AUTOSAR XML (schema 4-3-0)
standard types defined: Boolean, UInt8, SInt8, UInt16, SInt16, UInt32, SInt32, boolean, uint8, sint8, uint16, sint16, uint32, sint32
package /Components
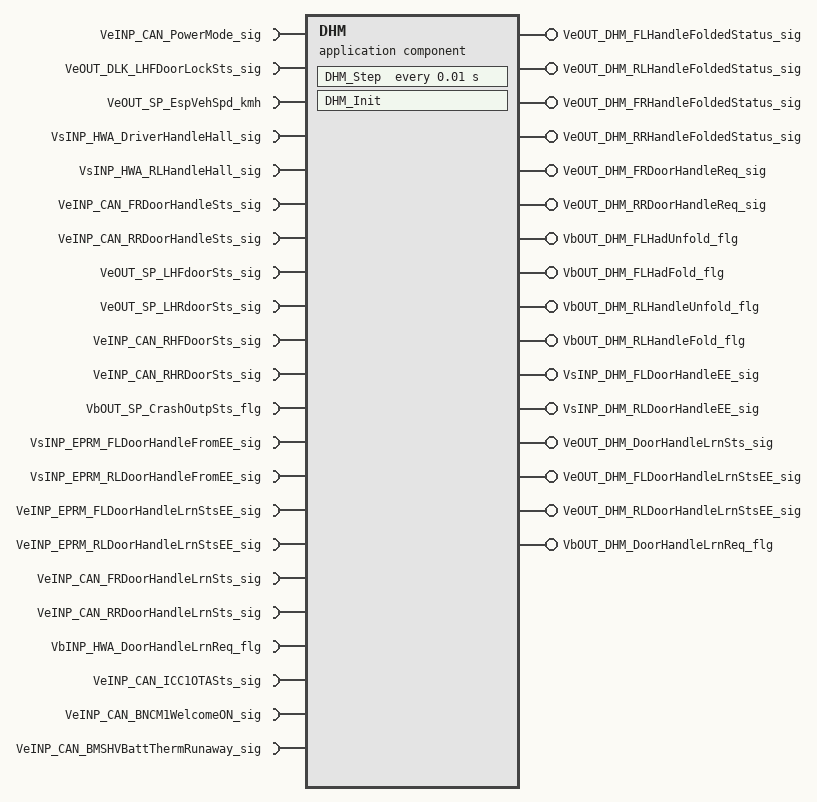
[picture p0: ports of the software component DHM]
  application sw component type DHM
    22 x require port:
      VeINP_CAN_PowerMode_sig: nonqueued-receiver-com-spec{data-element=VeINP_CAN_PowerMode_sig, init-value=0}, required-interface=VeINP_CAN_PowerMode_sig
      VeOUT_DLK_LHFDoorLockSts_sig: nonqueued-receiver-com-spec{data-element=VeOUT_DLK_LHFDoorLockSts_sig, init-value=0}, required-interface=VeOUT_DLK_LHFDoorLockSts_sig
      VeOUT_SP_EspVehSpd_kmh: nonqueued-receiver-com-spec{data-element=VeOUT_SP_EspVehSpd_kmh, init-value=0}, required-interface=VeOUT_SP_EspVehSpd_kmh
      VsINP_HWA_DriverHandleHall_sig: nonqueued-receiver-com-spec{data-element=VsINP_HWA_DriverHandleHall_sig, init-value=0}, required-interface=VsINP_HWA_DriverHandleHall_sig
      VsINP_HWA_RLHandleHall_sig: nonqueued-receiver-com-spec{data-element=VsINP_HWA_RLHandleHall_sig, init-value=0}, required-interface=VsINP_HWA_RLHandleHall_sig
      VeINP_CAN_FRDoorHandleSts_sig: nonqueued-receiver-com-spec{data-element=VeINP_CAN_FRDoorHandleSts_sig, init-value=0}, required-interface=VeINP_CAN_FRDoorHandleSts_sig
      VeINP_CAN_RRDoorHandleSts_sig: nonqueued-receiver-com-spec{data-element=VeINP_CAN_RRDoorHandleSts_sig, init-value=0}, required-interface=VeINP_CAN_RRDoorHandleSts_sig
      VeOUT_SP_LHFdoorSts_sig: nonqueued-receiver-com-spec{data-element=VeOUT_SP_LHFdoorSts_sig, init-value=0}, required-interface=VeOUT_SP_LHFdoorSts_sig
      VeOUT_SP_LHRdoorSts_sig: nonqueued-receiver-com-spec{data-element=VeOUT_SP_LHRdoorSts_sig, init-value=0}, required-interface=VeOUT_SP_LHRdoorSts_sig
      VeINP_CAN_RHFDoorSts_sig: nonqueued-receiver-com-spec{data-element=VeINP_CAN_RHFDoorSts_sig, init-value=0}, required-interface=VeINP_CAN_RHFDoorSts_sig
      VeINP_CAN_RHRDoorSts_sig: nonqueued-receiver-com-spec{data-element=VeINP_CAN_RHRDoorSts_sig, init-value=0}, required-interface=VeINP_CAN_RHRDoorSts_sig
      VbOUT_SP_CrashOutpSts_flg: nonqueued-receiver-com-spec{data-element=VbOUT_SP_CrashOutpSts_flg, init-value=0}, required-interface=VbOUT_SP_CrashOutpSts_flg
      VsINP_EPRM_FLDoorHandleFromEE_sig: nonqueued-receiver-com-spec{data-element=VsINP_EPRM_FLDoorHandleFromEE_sig, init-value=0}, required-interface=VsINP_EPRM_FLDoorHandleFromEE_sig
      VsINP_EPRM_RLDoorHandleFromEE_sig: nonqueued-receiver-com-spec{data-element=VsINP_EPRM_RLDoorHandleFromEE_sig, init-value=0}, required-interface=VsINP_EPRM_RLDoorHandleFromEE_sig
      VeINP_EPRM_FLDoorHandleLrnStsEE_sig: nonqueued-receiver-com-spec{data-element=VeINP_EPRM_FLDoorHandleLrnStsEE_sig, init-value=0}, required-interface=VeINP_EPRM_FLDoorHandleLrnStsEE_sig
      VeINP_EPRM_RLDoorHandleLrnStsEE_sig: nonqueued-receiver-com-spec{data-element=VeINP_EPRM_RLDoorHandleLrnStsEE_sig, init-value=0}, required-interface=VeINP_EPRM_RLDoorHandleLrnStsEE_sig
      VeINP_CAN_FRDoorHandleLrnSts_sig: nonqueued-receiver-com-spec{data-element=VeINP_CAN_FRDoorHandleLrnSts_sig, init-value=0}, required-interface=VeINP_CAN_FRDoorHandleLrnSts_sig
      VeINP_CAN_RRDoorHandleLrnSts_sig: nonqueued-receiver-com-spec{data-element=VeINP_CAN_RRDoorHandleLrnSts_sig, init-value=0}, required-interface=VeINP_CAN_RRDoorHandleLrnSts_sig
      VbINP_HWA_DoorHandleLrnReq_flg: nonqueued-receiver-com-spec{data-element=VbINP_HWA_DoorHandleLrnReq_flg, init-value=0}, required-interface=VbINP_HWA_DoorHandleLrnReq_flg
      VeINP_CAN_ICC1OTASts_sig: nonqueued-receiver-com-spec{data-element=VeINP_CAN_ICC1OTASts_sig, init-value=0}, required-interface=VeINP_CAN_ICC1OTASts_sig
      VeINP_CAN_BNCM1WelcomeON_sig: nonqueued-receiver-com-spec{data-element=VeINP_CAN_BNCM1WelcomeON_sig, init-value=0}, required-interface=VeINP_CAN_BNCM1WelcomeON_sig
      VeINP_CAN_BMSHVBattThermRunaway_sig: nonqueued-receiver-com-spec{data-element=VeINP_CAN_BMSHVBattThermRunaway_sig, init-value=0}, required-interface=VeINP_CAN_BMSHVBattThermRunaway_sig
    16 x provide port:
      VeOUT_DHM_FLHandleFoldedStatus_sig: nonqueued-sender-com-spec{data-element=VeOUT_DHM_FLHandleFoldedStatus_sig, init-value=0}, provided-interface=VeOUT_DHM_FLHandleFoldedStatus_sig
      VeOUT_DHM_RLHandleFoldedStatus_sig: nonqueued-sender-com-spec{data-element=VeOUT_DHM_RLHandleFoldedStatus_sig, init-value=0}, provided-interface=VeOUT_DHM_RLHandleFoldedStatus_sig
      VeOUT_DHM_FRHandleFoldedStatus_sig: nonqueued-sender-com-spec{data-element=VeOUT_DHM_FRHandleFoldedStatus_sig, init-value=0}, provided-interface=VeOUT_DHM_FRHandleFoldedStatus_sig
      VeOUT_DHM_RRHandleFoldedStatus_sig: nonqueued-sender-com-spec{data-element=VeOUT_DHM_RRHandleFoldedStatus_sig, init-value=0}, provided-interface=VeOUT_DHM_RRHandleFoldedStatus_sig
      VeOUT_DHM_FRDoorHandleReq_sig: nonqueued-sender-com-spec{data-element=VeOUT_DHM_FRDoorHandleReq_sig, init-value=0}, provided-interface=VeOUT_DHM_FRDoorHandleReq_sig
      VeOUT_DHM_RRDoorHandleReq_sig: nonqueued-sender-com-spec{data-element=VeOUT_DHM_RRDoorHandleReq_sig, init-value=0}, provided-interface=VeOUT_DHM_RRDoorHandleReq_sig
      VbOUT_DHM_FLHadUnfold_flg: nonqueued-sender-com-spec{data-element=VbOUT_DHM_FLHadUnfold_flg, init-value=0}, provided-interface=VbOUT_DHM_FLHadUnfold_flg
      VbOUT_DHM_FLHadFold_flg: nonqueued-sender-com-spec{data-element=VbOUT_DHM_FLHadFold_flg, init-value=0}, provided-interface=VbOUT_DHM_FLHadFold_flg
      VbOUT_DHM_RLHandleUnfold_flg: nonqueued-sender-com-spec{data-element=VbOUT_DHM_RLHandleUnfold_flg, init-value=0}, provided-interface=VbOUT_DHM_RLHandleUnfold_flg
      VbOUT_DHM_RLHandleFold_flg: nonqueued-sender-com-spec{data-element=VbOUT_DHM_RLHandleFold_flg, init-value=0}, provided-interface=VbOUT_DHM_RLHandleFold_flg
      VsINP_DHM_FLDoorHandleEE_sig: nonqueued-sender-com-spec{data-element=VsINP_DHM_FLDoorHandleEE_sig, init-value=0}, provided-interface=VsINP_DHM_FLDoorHandleEE_sig
      VsINP_DHM_RLDoorHandleEE_sig: nonqueued-sender-com-spec{data-element=VsINP_DHM_RLDoorHandleEE_sig, init-value=0}, provided-interface=VsINP_DHM_RLDoorHandleEE_sig
      VeOUT_DHM_DoorHandleLrnSts_sig: nonqueued-sender-com-spec{data-element=VeOUT_DHM_DoorHandleLrnSts_sig, init-value=0}, provided-interface=VeOUT_DHM_DoorHandleLrnSts_sig
      VeOUT_DHM_FLDoorHandleLrnStsEE_sig: nonqueued-sender-com-spec{data-element=VeOUT_DHM_FLDoorHandleLrnStsEE_sig, init-value=0}, provided-interface=VeOUT_DHM_FLDoorHandleLrnStsEE_sig
      VeOUT_DHM_RLDoorHandleLrnStsEE_sig: nonqueued-sender-com-spec{data-element=VeOUT_DHM_RLDoorHandleLrnStsEE_sig, init-value=0}, provided-interface=VeOUT_DHM_RLDoorHandleLrnStsEE_sig
      VbOUT_DHM_DoorHandleLrnReq_flg: nonqueued-sender-com-spec{data-element=VbOUT_DHM_DoorHandleLrnReq_flg, init-value=0}, provided-interface=VbOUT_DHM_DoorHandleLrnReq_flg
    behavior DHM: data-type-mapping=DataTypeMappingsSet, handle-termination-and-restart=NO-SUPPORT
      init event DHM_InitEvent: start-on-event=DHM_Init
      timing event Event_Runnable_Step: start-on-event=DHM_Step, period=0.01
      runnable DHM_Init
      runnable DHM_Step
        data-receive-point-by-arguments:
          22 x access:
            IN_VeINP_CAN_PowerMode_sig_VeINP_CAN_PowerMode_sig: accessed-variable=VeINP_CAN_PowerMode_sig.VeINP_CAN_PowerMode_sig
            IN_VeOUT_DLK_LHFDoorLockSts_sig_VeOUT_DLK_LHFDoorLockSts_sig: accessed-variable=VeOUT_DLK_LHFDoorLockSts_sig.VeOUT_DLK_LHFDoorLockSts_sig
            IN_VeOUT_SP_EspVehSpd_kmh_VeOUT_SP_EspVehSpd_kmh: accessed-variable=VeOUT_SP_EspVehSpd_kmh.VeOUT_SP_EspVehSpd_kmh
            IN_VsINP_HWA_DriverHandleHall_sig_VsINP_HWA_DriverHandleHall_sig: accessed-variable=VsINP_HWA_DriverHandleHall_sig.VsINP_HWA_DriverHandleHall_sig
            IN_VsINP_HWA_RLHandleHall_sig_VsINP_HWA_RLHandleHall_sig: accessed-variable=VsINP_HWA_RLHandleHall_sig.VsINP_HWA_RLHandleHall_sig
            IN_VeINP_CAN_FRDoorHandleSts_sig_VeINP_CAN_FRDoorHandleSts_sig: accessed-variable=VeINP_CAN_FRDoorHandleSts_sig.VeINP_CAN_FRDoorHandleSts_sig
            IN_VeINP_CAN_RRDoorHandleSts_sig_VeINP_CAN_RRDoorHandleSts_sig: accessed-variable=VeINP_CAN_RRDoorHandleSts_sig.VeINP_CAN_RRDoorHandleSts_sig
            IN_VeOUT_SP_LHFdoorSts_sig_VeOUT_SP_LHFdoorSts_sig: accessed-variable=VeOUT_SP_LHFdoorSts_sig.VeOUT_SP_LHFdoorSts_sig
            IN_VeOUT_SP_LHRdoorSts_sig_VeOUT_SP_LHRdoorSts_sig: accessed-variable=VeOUT_SP_LHRdoorSts_sig.VeOUT_SP_LHRdoorSts_sig
            IN_VeINP_CAN_RHFDoorSts_sig_VeINP_CAN_RHFDoorSts_sig: accessed-variable=VeINP_CAN_RHFDoorSts_sig.VeINP_CAN_RHFDoorSts_sig
            IN_VeINP_CAN_RHRDoorSts_sig_VeINP_CAN_RHRDoorSts_sig: accessed-variable=VeINP_CAN_RHRDoorSts_sig.VeINP_CAN_RHRDoorSts_sig
            IN_VbOUT_SP_CrashOutpSts_flg_VbOUT_SP_CrashOutpSts_flg: accessed-variable=VbOUT_SP_CrashOutpSts_flg.VbOUT_SP_CrashOutpSts_flg
            IN_VsINP_EPRM_FLDoorHandleFromEE_sig_VsINP_EPRM_FLDoorHandleFromEE_sig: accessed-variable=VsINP_EPRM_FLDoorHandleFromEE_sig.VsINP_EPRM_FLDoorHandleFromEE_sig
            IN_VsINP_EPRM_RLDoorHandleFromEE_sig_VsINP_EPRM_RLDoorHandleFromEE_sig: accessed-variable=VsINP_EPRM_RLDoorHandleFromEE_sig.VsINP_EPRM_RLDoorHandleFromEE_sig
            IN_VeINP_EPRM_FLDoorHandleLrnStsEE_sig_VeINP_EPRM_FLDoorHandleLrnStsEE_sig: accessed-variable=VeINP_EPRM_FLDoorHandleLrnStsEE_sig.VeINP_EPRM_FLDoorHandleLrnStsEE_sig
            IN_VeINP_EPRM_RLDoorHandleLrnStsEE_sig_VeINP_EPRM_RLDoorHandleLrnStsEE_sig: accessed-variable=VeINP_EPRM_RLDoorHandleLrnStsEE_sig.VeINP_EPRM_RLDoorHandleLrnStsEE_sig
            IN_VeINP_CAN_FRDoorHandleLrnSts_sig_VeINP_CAN_FRDoorHandleLrnSts_sig: accessed-variable=VeINP_CAN_FRDoorHandleLrnSts_sig.VeINP_CAN_FRDoorHandleLrnSts_sig
            IN_VeINP_CAN_RRDoorHandleLrnSts_sig_VeINP_CAN_RRDoorHandleLrnSts_sig: accessed-variable=VeINP_CAN_RRDoorHandleLrnSts_sig.VeINP_CAN_RRDoorHandleLrnSts_sig
            IN_VbINP_HWA_DoorHandleLrnReq_flg_VbINP_HWA_DoorHandleLrnReq_flg: accessed-variable=VbINP_HWA_DoorHandleLrnReq_flg.VbINP_HWA_DoorHandleLrnReq_flg
            IN_VeINP_CAN_ICC1OTASts_sig_VeINP_CAN_ICC1OTASts_sig: accessed-variable=VeINP_CAN_ICC1OTASts_sig.VeINP_CAN_ICC1OTASts_sig
            IN_VeINP_CAN_BNCM1WelcomeON_sig_VeINP_CAN_BNCM1WelcomeON_sig: accessed-variable=VeINP_CAN_BNCM1WelcomeON_sig.VeINP_CAN_BNCM1WelcomeON_sig
            IN_VeINP_CAN_BMSHVBattThermRunaway_sig_VeINP_CAN_BMSHVBattThermRunaway_sig: accessed-variable=VeINP_CAN_BMSHVBattThermRunaway_sig.VeINP_CAN_BMSHVBattThermRunaway_sig
        data-send-points:
          16 x access:
            OUT_VeOUT_DHM_FLHandleFoldedStatus_sig_VeOUT_DHM_FLHandleFoldedStatus_sig: accessed-variable=VeOUT_DHM_FLHandleFoldedStatus_sig.VeOUT_DHM_FLHandleFoldedStatus_sig
            OUT_VeOUT_DHM_RLHandleFoldedStatus_sig_VeOUT_DHM_RLHandleFoldedStatus_sig: accessed-variable=VeOUT_DHM_RLHandleFoldedStatus_sig.VeOUT_DHM_RLHandleFoldedStatus_sig
            OUT_VeOUT_DHM_FRHandleFoldedStatus_sig_VeOUT_DHM_FRHandleFoldedStatus_sig: accessed-variable=VeOUT_DHM_FRHandleFoldedStatus_sig.VeOUT_DHM_FRHandleFoldedStatus_sig
            OUT_VeOUT_DHM_RRHandleFoldedStatus_sig_VeOUT_DHM_RRHandleFoldedStatus_sig: accessed-variable=VeOUT_DHM_RRHandleFoldedStatus_sig.VeOUT_DHM_RRHandleFoldedStatus_sig
            OUT_VeOUT_DHM_FRDoorHandleReq_sig_VeOUT_DHM_FRDoorHandleReq_sig: accessed-variable=VeOUT_DHM_FRDoorHandleReq_sig.VeOUT_DHM_FRDoorHandleReq_sig
            OUT_VeOUT_DHM_RRDoorHandleReq_sig_VeOUT_DHM_RRDoorHandleReq_sig: accessed-variable=VeOUT_DHM_RRDoorHandleReq_sig.VeOUT_DHM_RRDoorHandleReq_sig
            OUT_VbOUT_DHM_FLHadUnfold_flg_VbOUT_DHM_FLHadUnfold_flg: accessed-variable=VbOUT_DHM_FLHadUnfold_flg.VbOUT_DHM_FLHadUnfold_flg
            OUT_VbOUT_DHM_FLHadFold_flg_VbOUT_DHM_FLHadFold_flg: accessed-variable=VbOUT_DHM_FLHadFold_flg.VbOUT_DHM_FLHadFold_flg
            OUT_VbOUT_DHM_RLHandleUnfold_flg_VbOUT_DHM_RLHandleUnfold_flg: accessed-variable=VbOUT_DHM_RLHandleUnfold_flg.VbOUT_DHM_RLHandleUnfold_flg
            OUT_VbOUT_DHM_RLHandleFold_flg_VbOUT_DHM_RLHandleFold_flg: accessed-variable=VbOUT_DHM_RLHandleFold_flg.VbOUT_DHM_RLHandleFold_flg
            OUT_VsINP_DHM_FLDoorHandleEE_sig_VsINP_DHM_FLDoorHandleEE_sig: accessed-variable=VsINP_DHM_FLDoorHandleEE_sig.VsINP_DHM_FLDoorHandleEE_sig
            OUT_VsINP_DHM_RLDoorHandleEE_sig_VsINP_DHM_RLDoorHandleEE_sig: accessed-variable=VsINP_DHM_RLDoorHandleEE_sig.VsINP_DHM_RLDoorHandleEE_sig
            OUT_VeOUT_DHM_DoorHandleLrnSts_sig_VeOUT_DHM_DoorHandleLrnSts_sig: accessed-variable=VeOUT_DHM_DoorHandleLrnSts_sig.VeOUT_DHM_DoorHandleLrnSts_sig
            OUT_VeOUT_DHM_FLDoorHandleLrnStsEE_sig_VeOUT_DHM_FLDoorHandleLrnStsEE_sig: accessed-variable=VeOUT_DHM_FLDoorHandleLrnStsEE_sig.VeOUT_DHM_FLDoorHandleLrnStsEE_sig
            OUT_VeOUT_DHM_RLDoorHandleLrnStsEE_sig_VeOUT_DHM_RLDoorHandleLrnStsEE_sig: accessed-variable=VeOUT_DHM_RLDoorHandleLrnStsEE_sig.VeOUT_DHM_RLDoorHandleLrnStsEE_sig
            OUT_VbOUT_DHM_DoorHandleLrnReq_flg_VbOUT_DHM_DoorHandleLrnReq_flg: accessed-variable=VbOUT_DHM_DoorHandleLrnReq_flg.VbOUT_DHM_DoorHandleLrnReq_flg
package /Interfaces
  38 x sender receiver interface:
    VeINP_CAN_PowerMode_sig
      data VeINP_CAN_PowerMode_sig: category=VALUE, sw-calibration-access=READ-ONLY, type=UInt8
    VeOUT_DLK_LHFDoorLockSts_sig
      data VeOUT_DLK_LHFDoorLockSts_sig: category=VALUE, sw-calibration-access=READ-ONLY, type=UInt8
    VeOUT_SP_EspVehSpd_kmh
      data VeOUT_SP_EspVehSpd_kmh: category=VALUE, sw-calibration-access=READ-ONLY, type=UInt8
    VsINP_HWA_DriverHandleHall_sig
      data VsINP_HWA_DriverHandleHall_sig: category=VALUE, sw-calibration-access=READ-ONLY, type=SInt16
    VsINP_HWA_RLHandleHall_sig
      data VsINP_HWA_RLHandleHall_sig: category=VALUE, sw-calibration-access=READ-ONLY, type=SInt16
    VeINP_CAN_FRDoorHandleSts_sig
      data VeINP_CAN_FRDoorHandleSts_sig: category=VALUE, sw-calibration-access=READ-ONLY, type=UInt8
    VeINP_CAN_RRDoorHandleSts_sig
      data VeINP_CAN_RRDoorHandleSts_sig: category=VALUE, sw-calibration-access=READ-ONLY, type=UInt8
    VeOUT_SP_LHFdoorSts_sig
      data VeOUT_SP_LHFdoorSts_sig: category=VALUE, sw-calibration-access=READ-ONLY, type=UInt8
    VeOUT_SP_LHRdoorSts_sig
      data VeOUT_SP_LHRdoorSts_sig: category=VALUE, sw-calibration-access=READ-ONLY, type=UInt8
    VeINP_CAN_RHFDoorSts_sig
      data VeINP_CAN_RHFDoorSts_sig: category=VALUE, sw-calibration-access=READ-ONLY, type=UInt8
    VeINP_CAN_RHRDoorSts_sig
      data VeINP_CAN_RHRDoorSts_sig: category=VALUE, sw-calibration-access=READ-ONLY, type=UInt8
    VbOUT_SP_CrashOutpSts_flg
      data VbOUT_SP_CrashOutpSts_flg: category=BOOLEAN, sw-calibration-access=READ-ONLY, type=Boolean
    VsINP_EPRM_FLDoorHandleFromEE_sig
      data VsINP_EPRM_FLDoorHandleFromEE_sig: category=VALUE, sw-calibration-access=READ-ONLY, type=SInt16
    VsINP_EPRM_RLDoorHandleFromEE_sig
      data VsINP_EPRM_RLDoorHandleFromEE_sig: category=VALUE, sw-calibration-access=READ-ONLY, type=SInt16
    VeINP_EPRM_FLDoorHandleLrnStsEE_sig
      data VeINP_EPRM_FLDoorHandleLrnStsEE_sig: category=VALUE, sw-calibration-access=READ-ONLY, type=UInt8
    VeINP_EPRM_RLDoorHandleLrnStsEE_sig
      data VeINP_EPRM_RLDoorHandleLrnStsEE_sig: category=VALUE, sw-calibration-access=READ-ONLY, type=UInt8
    VeINP_CAN_FRDoorHandleLrnSts_sig
      data VeINP_CAN_FRDoorHandleLrnSts_sig: category=VALUE, sw-calibration-access=READ-ONLY, type=UInt8
    VeINP_CAN_RRDoorHandleLrnSts_sig
      data VeINP_CAN_RRDoorHandleLrnSts_sig: category=VALUE, sw-calibration-access=READ-ONLY, type=UInt8
    VbINP_HWA_DoorHandleLrnReq_flg
      data VbINP_HWA_DoorHandleLrnReq_flg: category=BOOLEAN, sw-calibration-access=READ-ONLY, type=Boolean
    VeINP_CAN_ICC1OTASts_sig
      data VeINP_CAN_ICC1OTASts_sig: category=VALUE, sw-calibration-access=READ-ONLY, type=UInt8
    VeINP_CAN_BNCM1WelcomeON_sig
      data VeINP_CAN_BNCM1WelcomeON_sig: category=VALUE, sw-calibration-access=READ-ONLY, type=UInt8
    VeINP_CAN_BMSHVBattThermRunaway_sig
      data VeINP_CAN_BMSHVBattThermRunaway_sig: category=VALUE, sw-calibration-access=READ-ONLY, type=UInt8
    VeOUT_DHM_FLHandleFoldedStatus_sig
      data VeOUT_DHM_FLHandleFoldedStatus_sig: category=VALUE, sw-calibration-access=READ-ONLY, type=UInt8
    VeOUT_DHM_RLHandleFoldedStatus_sig
      data VeOUT_DHM_RLHandleFoldedStatus_sig: category=VALUE, sw-calibration-access=READ-ONLY, type=UInt8
    VeOUT_DHM_FRHandleFoldedStatus_sig
      data VeOUT_DHM_FRHandleFoldedStatus_sig: category=VALUE, sw-calibration-access=READ-ONLY, type=UInt8
    VeOUT_DHM_RRHandleFoldedStatus_sig
      data VeOUT_DHM_RRHandleFoldedStatus_sig: category=VALUE, sw-calibration-access=READ-ONLY, type=UInt8
    VeOUT_DHM_FRDoorHandleReq_sig
      data VeOUT_DHM_FRDoorHandleReq_sig: category=VALUE, sw-calibration-access=READ-ONLY, type=UInt8
    VeOUT_DHM_RRDoorHandleReq_sig
      data VeOUT_DHM_RRDoorHandleReq_sig: category=VALUE, sw-calibration-access=READ-ONLY, type=UInt8
    VbOUT_DHM_FLHadUnfold_flg
      data VbOUT_DHM_FLHadUnfold_flg: category=BOOLEAN, sw-calibration-access=READ-ONLY, type=Boolean
    VbOUT_DHM_FLHadFold_flg
      data VbOUT_DHM_FLHadFold_flg: category=BOOLEAN, sw-calibration-access=READ-ONLY, type=Boolean
    VbOUT_DHM_RLHandleUnfold_flg
      data VbOUT_DHM_RLHandleUnfold_flg: category=BOOLEAN, sw-calibration-access=READ-ONLY, type=Boolean
    VbOUT_DHM_RLHandleFold_flg
      data VbOUT_DHM_RLHandleFold_flg: category=BOOLEAN, sw-calibration-access=READ-ONLY, type=Boolean
    VsINP_DHM_FLDoorHandleEE_sig
      data VsINP_DHM_FLDoorHandleEE_sig: category=VALUE, sw-calibration-access=READ-ONLY, type=SInt16
    VsINP_DHM_RLDoorHandleEE_sig
      data VsINP_DHM_RLDoorHandleEE_sig: category=VALUE, sw-calibration-access=READ-ONLY, type=SInt16
    VeOUT_DHM_DoorHandleLrnSts_sig
      data VeOUT_DHM_DoorHandleLrnSts_sig: category=VALUE, sw-calibration-access=READ-ONLY, type=UInt8
    VeOUT_DHM_FLDoorHandleLrnStsEE_sig
      data VeOUT_DHM_FLDoorHandleLrnStsEE_sig: category=VALUE, sw-calibration-access=READ-ONLY, type=UInt8
    VeOUT_DHM_RLDoorHandleLrnStsEE_sig
      data VeOUT_DHM_RLDoorHandleLrnStsEE_sig: category=VALUE, sw-calibration-access=READ-ONLY, type=UInt8
    VbOUT_DHM_DoorHandleLrnReq_flg
      data VbOUT_DHM_DoorHandleLrnReq_flg: category=BOOLEAN, sw-calibration-access=READ-ONLY, type=Boolean
package /DHM_imp
  swc implementation DHM: behavior=DHM
    code-descriptors:
      code Default: artifact-descriptors=autosar-engineering-object={short-label=Default, category=SWSRC}
package /DataTypes/SwAddrMethods
  sw addr method CODE: section-type=CODE
  sw addr method CONST: section-type=CONST
  sw addr method VAR: section-type=VAR
package /DataTypes/ApplicationDataTypes
  7 x app type, all with sw-calibration-access=READ-WRITE:
    Boolean: category=BOOLEAN, compu {0=FALSE, 1=TRUE}
    UInt8: category=VALUE, compu {identical}, range phys 0..255
    SInt8: category=VALUE, compu {identical}, range phys -128..127
    UInt16: category=VALUE, compu {identical}, range phys 0..65535
    SInt16: category=VALUE, compu {identical}, range phys -32768..32767
    UInt32: category=VALUE, compu {identical}, range phys 0..4294967295
    SInt32: category=VALUE, compu {identical}, range phys -2147483648..2147483647
  9 x application record data type, all with category=STRUCTURE, sw-calibration-access=READ-WRITE:
    ESC_AngleMotorOut_STRUCT
      4 x application record element:
        LearnSts: category=VALUE, type=UInt8
        CorrectPos_Zero: category=BOOLEAN, type=Boolean
        CorrectPos_Max: category=BOOLEAN, type=Boolean
        ManualCorrectPos: category=VALUE, type=UInt8
    ESC_TelesMotorOut_STRUCT
      4 x application record element:
        LearnSts: category=VALUE, type=UInt8
        CorrectPos_Zero: category=BOOLEAN, type=Boolean
        CorrectPos_Max: category=BOOLEAN, type=Boolean
        ManualCorrectPos: category=VALUE, type=UInt8
    ESC_AngleDebugInfo_STRUCT
      4 x application record element:
        LearnSts: category=VALUE, type=UInt8
        CorrectPos_Zero: category=BOOLEAN, type=Boolean
        CorrectPos_Max: category=BOOLEAN, type=Boolean
        ManualCorrectPos: category=VALUE, type=UInt8
    SteerWheel_TarPosSts_STRUCT
      application record element AngleTarPos: category=VALUE, type=SInt16
      application record element FrontBackTarPos: category=VALUE, type=SInt16
    MIR_EPRMSts_STRUCT
      8 x application record element, all with category=VALUE, type=UInt8:
        L_SaveDrvMode_VtcPos
        L_SaveDrvMode_HrzPos
        L_SaveTiltMode_VtcPos
        L_SaveTiltMode_HrzPos
        R_SaveDrvMode_VtcPos
        R_SaveDrvMode_HrzPos
        R_SaveTiltMode_VtcPos
        R_SaveTiltMode_HrzPos
    MIR_ADJ_STRUCT
      application record element L_Mir_Current_VtcPos: category=VALUE, type=UInt8
      application record element L_Mir_Current_HrzPos: category=VALUE, type=UInt8
    SEAT_DrvOutputs_STRUCT
      4 x application record element:
        LearnSts: category=VALUE, type=UInt8
        CorrectPos_Zero: category=BOOLEAN, type=Boolean
        CorrectPos_Max: category=BOOLEAN, type=Boolean
        ManualCorrectPos: category=VALUE, type=UInt8
    SDU_EPRMTarPosSts_STRUCT
      5 x application record element, all with category=VALUE, type=SInt16:
        HorizTarPos
        VertiTarPos
        BkAnTarPos
        CushTarPos
        LegTarPos
    TURN_DIAG_STRUCT
      5 x application record element:
        OpenLoad: category=BOOLEAN, type=Boolean
        Overload: category=BOOLEAN, type=Boolean
        NormA2D: category=VALUE, type=UInt8
        Turn_LTH: category=VALUE, type=UInt8
        TurnCalib_th: category=VALUE, type=UInt8
  application array data type rt_Array_UInt8_8: category=ARRAY, sw-calibration-access=READ-WRITE
    element rt_Array_UInt8_8: category=VALUE, type=UInt8, array-size-semantics=FIXED-SIZE, max-number-of-elements=8
package /DataTypes/ApplicationDataTypes/DataConstrs
  range DC_ESC_AngleMotorOut_STRUCT: phys 0
  range DC_ESC_TelesMotorOut_STRUCT: phys 0
  range DC_ESC_AngleDebugInfo_STRUCT: phys 0
  range DC_SteerWheel_TarPosSts_STRUCT: phys 0
  range DC_MIR_EPRMSts_STRUCT: phys 0
  range DC_MIR_ADJ_STRUCT: phys 0
  range DC_SEAT_DrvOutputs_STRUCT: phys 0
  range DC_SDU_EPRMTarPosSts_STRUCT: phys 0
  range DC_TURN_DIAG_STRUCT: phys 0
package /DataTypes/ImplementationDataTypes
  10 x impl type:
    ESC_AngleMotorOut_STRUCT: category=STRUCTURE
      4 x element, all with category=TYPE_REFERENCE:
        LearnSts: implementation-data-type=UInt8
        CorrectPos_Zero: implementation-data-type=Boolean
        CorrectPos_Max: implementation-data-type=Boolean
        ManualCorrectPos: implementation-data-type=UInt8
    ESC_TelesMotorOut_STRUCT: category=STRUCTURE
      4 x element, all with category=TYPE_REFERENCE:
        LearnSts: implementation-data-type=UInt8
        CorrectPos_Zero: implementation-data-type=Boolean
        CorrectPos_Max: implementation-data-type=Boolean
        ManualCorrectPos: implementation-data-type=UInt8
    ESC_AngleDebugInfo_STRUCT: category=STRUCTURE
      4 x element, all with category=TYPE_REFERENCE:
        LearnSts: implementation-data-type=UInt8
        CorrectPos_Zero: implementation-data-type=Boolean
        CorrectPos_Max: implementation-data-type=Boolean
        ManualCorrectPos: implementation-data-type=UInt8
    SteerWheel_TarPosSts_STRUCT: category=STRUCTURE
      element AngleTarPos: implementation-data-type=SInt16
      element FrontBackTarPos: implementation-data-type=SInt16
    MIR_EPRMSts_STRUCT: category=STRUCTURE
      8 x element, all with category=TYPE_REFERENCE, implementation-data-type=UInt8:
        L_SaveDrvMode_VtcPos
        L_SaveDrvMode_HrzPos
        L_SaveTiltMode_VtcPos
        L_SaveTiltMode_HrzPos
        R_SaveDrvMode_VtcPos
        R_SaveDrvMode_HrzPos
        R_SaveTiltMode_VtcPos
        R_SaveTiltMode_HrzPos
    MIR_ADJ_STRUCT: category=STRUCTURE
      element L_Mir_Current_VtcPos: implementation-data-type=UInt8
      element L_Mir_Current_HrzPos: implementation-data-type=UInt8
    SEAT_DrvOutputs_STRUCT: category=STRUCTURE
      4 x element, all with category=TYPE_REFERENCE:
        LearnSts: implementation-data-type=UInt8
        CorrectPos_Zero: implementation-data-type=Boolean
        CorrectPos_Max: implementation-data-type=Boolean
        ManualCorrectPos: implementation-data-type=UInt8
    SDU_EPRMTarPosSts_STRUCT: category=STRUCTURE
      5 x element, all with category=TYPE_REFERENCE, implementation-data-type=SInt16:
        HorizTarPos
        VertiTarPos
        BkAnTarPos
        CushTarPos
        LegTarPos
    TURN_DIAG_STRUCT: category=STRUCTURE
      5 x element, all with category=TYPE_REFERENCE:
        OpenLoad: implementation-data-type=Boolean
        Overload: implementation-data-type=Boolean
        NormA2D: implementation-data-type=UInt8
        Turn_LTH: implementation-data-type=UInt8
        TurnCalib_th: implementation-data-type=UInt8
    rt_Array_UInt8_8: category=ARRAY
      element rt_Array_UInt8_8: array-size=8, array-size-semantics=FIXED-SIZE, implementation-data-type=UInt8
package /DataTypes/Units
  unit NoUnit: factor-si-to-unit=1, offset-si-to-unit=0
package /DataTypes/DataTypeMappings
  data type mapping set DataTypeMappingsSet
    data-type-maps:
      application-data-type=Boolean, implementation-data-type=Boolean
      application-data-type=UInt8, implementation-data-type=UInt8
      application-data-type=SInt8, implementation-data-type=SInt8
      application-data-type=UInt16, implementation-data-type=UInt16
      application-data-type=SInt16, implementation-data-type=SInt16
      application-data-type=UInt32, implementation-data-type=UInt32
      application-data-type=SInt32, implementation-data-type=SInt32
      application-data-type=ESC_AngleMotorOut_STRUCT, implementation-data-type=ESC_AngleMotorOut_STRUCT
      application-data-type=ESC_TelesMotorOut_STRUCT, implementation-data-type=ESC_TelesMotorOut_STRUCT
      application-data-type=ESC_AngleDebugInfo_STRUCT, implementation-data-type=ESC_AngleDebugInfo_STRUCT
      application-data-type=SteerWheel_TarPosSts_STRUCT, implementation-data-type=SteerWheel_TarPosSts_STRUCT
      application-data-type=MIR_EPRMSts_STRUCT, implementation-data-type=MIR_EPRMSts_STRUCT
      application-data-type=MIR_ADJ_STRUCT, implementation-data-type=MIR_ADJ_STRUCT
      application-data-type=SEAT_DrvOutputs_STRUCT, implementation-data-type=SEAT_DrvOutputs_STRUCT
      application-data-type=SDU_EPRMTarPosSts_STRUCT, implementation-data-type=SDU_EPRMTarPosSts_STRUCT
      application-data-type=TURN_DIAG_STRUCT, implementation-data-type=TURN_DIAG_STRUCT
      application-data-type=rt_Array_UInt8_8, implementation-data-type=rt_Array_UInt8_8
